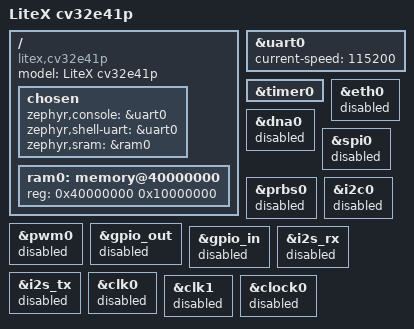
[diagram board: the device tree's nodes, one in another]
/*
 * Copyright (c) 2018 - 2019 Antmicro <www.antmicro.com>
 *
 * SPDX-License-Identifier: Apache-2.0
 */

/dts-v1/;

#include <riscv32-litex-cv32e41p.dtsi>

/ {
	model = "LiteX cv32e41p";
	compatible = "litex,cv32e41p";
	chosen {
		zephyr,console = &uart0;
		zephyr,shell-uart = &uart0;
		zephyr,sram = &ram0;
	};

	ram0: memory@40000000 {
		device_type = "memory";
		reg = <0x40000000 0x10000000>;
	};
};

&uart0 {
	status = "okay";
	current-speed = <115200>;
};

&timer0 {
	status = "okay";
};

&eth0 {
	status = "disabled";
};

&dna0 {
	status = "disabled";
};

&spi0 {
	status = "disabled";
};

&prbs0 {
	status = "disabled";
};

&i2c0 {
	status = "disabled";
};

&pwm0 {
	status = "disabled";
};

&gpio_out {
	status = "disabled";
};

&gpio_in {
	status = "disabled";
};

&i2s_rx {
	status = "disabled";
};

&i2s_tx {
	status = "disabled";
};

&clk0 {
	status = "disabled";
};

&clk1 {
	status = "disabled";
};

&clock0 {
	status = "disabled";
};
